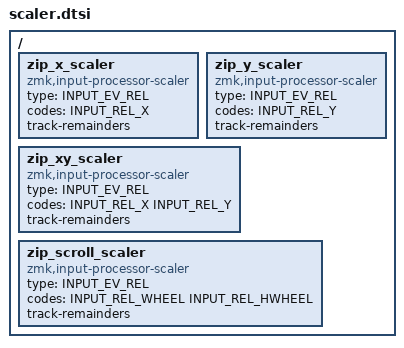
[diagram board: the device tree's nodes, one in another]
/*
 * Copyright (c) 2024 The ZMK Contributors
 *
 * SPDX-License-Identifier: MIT
 */

 #include <zephyr/dt-bindings/input/input-event-codes.h>

/ {
    /omit-if-no-ref/ zip_x_scaler: zip_x_scaler {
        compatible = "zmk,input-processor-scaler";
        #input-processor-cells = <2>;
        type = <INPUT_EV_REL>;
        codes = <INPUT_REL_X>;
        track-remainders;
    };

    /omit-if-no-ref/ zip_y_scaler: zip_y_scaler {
        compatible = "zmk,input-processor-scaler";
        #input-processor-cells = <2>;
        type = <INPUT_EV_REL>;
        codes = <INPUT_REL_Y>;
        track-remainders;
    };

    /omit-if-no-ref/ zip_xy_scaler: zip_xy_scaler {
        compatible = "zmk,input-processor-scaler";
        #input-processor-cells = <2>;
        type = <INPUT_EV_REL>;
        codes = <INPUT_REL_X INPUT_REL_Y>;
        track-remainders;
    };

    /omit-if-no-ref/ zip_scroll_scaler: zip_scroll_scaler {
        compatible = "zmk,input-processor-scaler";
        #input-processor-cells = <2>;
        type = <INPUT_EV_REL>;
        codes = <INPUT_REL_WHEEL INPUT_REL_HWHEEL>;
        track-remainders;
    };
};
